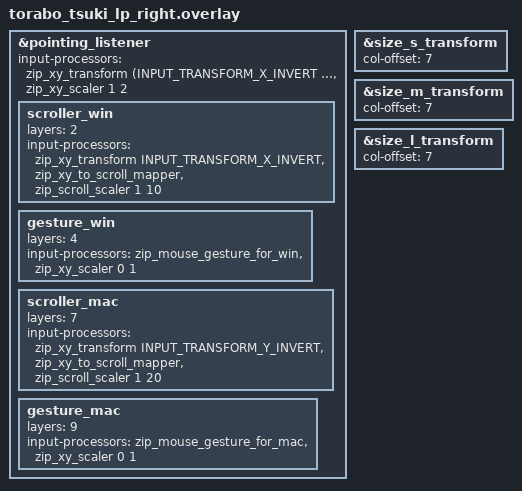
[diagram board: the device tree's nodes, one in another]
#include "torabo_tsuki_lp.dtsi"
#include <input/processors.dtsi>
#include <dt-bindings/zmk/input_transform.h>

&pointing_listener {
    input-processors =
        <&zip_xy_transform (INPUT_TRANSFORM_X_INVERT | INPUT_TRANSFORM_Y_INVERT)>,
        <&zip_xy_scaler 1 2>;

    scroller_win {
        layers = <2>;
        input-processors =
            <&zip_xy_transform INPUT_TRANSFORM_X_INVERT>,
            <&zip_xy_to_scroll_mapper>,
            <&zip_scroll_scaler 1 10>;
    };

    gesture_win {
        layers = <4>;
        input-processors = <
            &zip_mouse_gesture_for_win
            &zip_xy_scaler 0 1
        >;
    };

    scroller_mac {
        layers = <7>;
        input-processors =
            <&zip_xy_transform INPUT_TRANSFORM_Y_INVERT>,
            <&zip_xy_to_scroll_mapper>,
            <&zip_scroll_scaler 1 20>;
    };

    gesture_mac {
        layers = <9>;
        input-processors = <
            &zip_mouse_gesture_for_mac
            &zip_xy_scaler 0 1
        >;
    };
};

&size_s_transform {
    col-offset = <7>;
};

&size_m_transform {
    col-offset = <7>;
};

&size_l_transform {
    col-offset = <7>;
};
